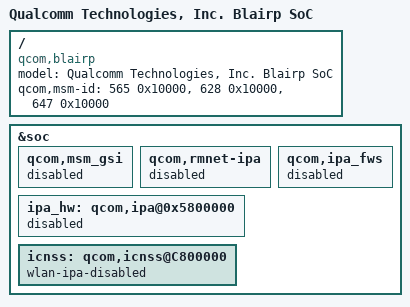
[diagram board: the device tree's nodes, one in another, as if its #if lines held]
/dts-v1/;

#include "blair.dtsi"

/ {
	model = "Qualcomm Technologies, Inc. Blairp SoC";
	compatible = "qcom,blairp";
#ifdef CONFIG_ARCH_SONY_ZAMBEZI
	qcom,msm-id = <565 0x10000>, <628 0x10000>, <647 0x10000>;
#else
	qcom,msm-id = <565 0x10000>, <628 0x10000>;
#endif
};

&soc {
	qcom,msm_gsi {
		status = "disabled";
	};

	qcom,rmnet-ipa {
		status = "disabled";
	};

	qcom,ipa_fws {
		status = "disabled";
	};

	ipa_hw: qcom,ipa@0x5800000 {
		status = "disabled";
	};

	icnss: qcom,icnss@C800000 {
		wlan-ipa-disabled;
	};

};
